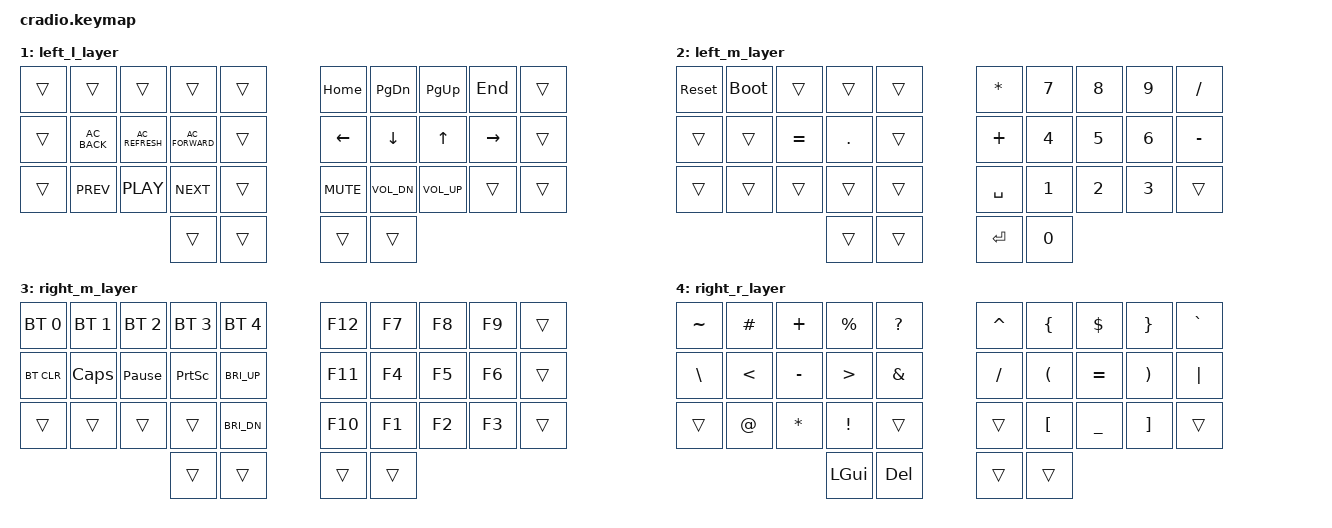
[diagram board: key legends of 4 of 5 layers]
// Copyright (c) 2022 The ZMK Contributors
// SPDX-License-Identifier: MIT

#include <behaviors.dtsi>
#include <dt-bindings/zmk/keys.h>
#include <dt-bindings/zmk/bt.h>

// Home row mods macro
#define HRML(k1,k2,k3,k4) &ht LGUI k1  &ht LALT k2  &ht LCTRL k3  &ht LSHFT k4
#define HRMR(k1,k2,k3,k4) &ht RSHFT k1  &ht RCTRL k2  &ht LALT k3  &ht RGUI k4

// Layers
#define DEFAULT 0
#define LEFT_L 1
#define LEFT_M 2
#define RIGHT_M 3
#define RIGHT_R 4

// Tapping term time
#define TAP_TERM 170

/ {
    behaviors {
        ht: hold_tap {
            compatible = "zmk,behavior-hold-tap";
            #binding-cells = <2>;
            flavor = "tap-preferred";
            tapping-term-ms = <TAP_TERM>;
            quick-tap-ms = <150>;
            require-prior-idle-ms = <100>;
            bindings = <&kp>, <&kp>;
        };
    };

    lt {
        tapping-term-ms = <TAP_TERM>;
    };

    // conditional_layers {
    //     compatible = "zmk,conditional-layers";
    //     tri_layer {
    //         if-layers = <1 2>;
    //         then-layer = <3>;
    //     };
    // };

    keymap {
        compatible = "zmk,keymap";
        default_layer {
            bindings = <
                //╭──────────┬──────────┬──────────┬──────────┬──────────╮   ╭──────────┬──────────┬──────────┬──────────┬──────────╮
                //│  W       │  L       │  Y       │  P       │  B       │   │  F       │  J       │  O       │  U       │  ' "     │
                &kp W      &kp L    &ht RALT Y   &kp P      &kp B          &kp F      &kp J     &ht RALT O    &kp U     &kp SQT
                //├──────────┼──────────┼──────────┼──────────┼──────────┤   ├──────────┼──────────┼──────────┼──────────┼──────────┤
                //│  C       │  R       │  S       │  T       │  G       │   │  M       │  N       │  E       │  I       │  A       │
                HRML(C,        R,         S,         T)     &kp G          &kp M      HRMR(N,        E,         I,        A)
                //├──────────┼──────────┼──────────┼──────────┼──────────┤   ├──────────┼──────────┼──────────┼──────────┼──────────┤
                //│  Q       │  Z       │  V       │  D       │  K       │   │  X       │  H       │ , <      │ . >      │ / ?      │
                &kp Q      &kp Z      &kp V      &kp D      &kp K          &kp X      &kp H      &kp SEMI   &kp COMMA   &kp DOT
                //╰──────────┴──────────┴──────────┼──────────┼──────────┤   ├──────────┼──────────┼──────────┴──────────┴──────────╯
                &lt LEFT_L TAB &lt LEFT_M SPACE &lt RIGHT_M BSPC &lt RIGHT_R ESC
                //                                 ╰──────────┴──────────╯   ╰──────────┴──────────╯
            >;
        };

        left_l_layer {
            bindings = <
                //╭──────────┬──────────┬──────────┬──────────┬──────────╮   ╭──────────┬──────────┬──────────┬──────────┬──────────╮
                //│          │          │          │          │          │   │  HOME    │PAGE DOWN │ PAGE UP  │  END     │          │
                &trans     &trans     &trans     &trans    &trans          &kp HOME   &kp PG_DN    &kp PG_UP   &kp END   &trans
                //├──────────┼──────────┼──────────┼──────────┼──────────┤   ├──────────┼──────────┼──────────┼──────────┼──────────┤
                //│          │  CAPS    │ PAUSE    │PRINT SCRN│          │   │  <-      │  v       │  ^       │  ->      │          │
                &trans &kp C_AC_BACK &kp C_AC_REFRESH &kp C_AC_FORWARD &trans  &kp LEFT  &kp DOWN  &kp UP     &kp RIGHT   &trans
                //├──────────┼──────────┼──────────┼──────────┼──────────┤   ├──────────┼──────────┼──────────┼──────────┼──────────┤
                //│          │MEDIA PREV│MEDIA PLAY│MEDIA NEXT│          │   │  MUTE    │VOL DOWN  │VOL UP    │          │          │
                &trans    &kp C_PREV &kp C_PLAY &kp C_NEXT   &trans       &kp C_MUTE &kp C_VOL_DN &kp C_VOL_UP &trans  &trans
                //╰──────────┴──────────┴──────────┼──────────┼──────────┤   ├──────────┼──────────┼──────────┴──────────┴──────────╯
                &trans     &trans         &trans     &trans
                //                                 ╰──────────┴──────────╯   ╰──────────┴──────────╯
            >;
        };

        left_m_layer {
            bindings = <
                //╭──────────┬──────────┬──────────┬──────────┬──────────╮   ╭──────────┬──────────┬──────────┬──────────┬──────────╮
                //│ RESET    │          │          │          │          │   │   *      │  7       │  8       │  9       │  /       │
                &sys_reset  &bootloader   &trans     &trans    &trans        &kp ASTRK   &kp N7     &kp N8      &kp N9    &kp FSLH
                //├──────────┼──────────┼──────────┼──────────┼──────────┤   ├──────────┼──────────┼──────────┼──────────┼──────────┤
                //│BOOTLOADER│          │  =       │  .       │          │   │   +      │  4       │  5       │  6       │  -       │
                &trans          &trans    &kp EQUAL  &kp DOT    &trans         &kp PLUS   &kp N4     &kp N5      &kp N6    &kp MINUS
                //├──────────┼──────────┼──────────┼──────────┼──────────┤   ├──────────┼──────────┼──────────┼──────────┼──────────┤
                //│          │          │          │          │          │   │ SPACE    │  1       │  2       │  3       │          │
                &trans     &trans     &trans     &trans     &trans        &kp SPACE    &kp N1    &kp N2      &kp N3      &trans
                //╰──────────┴──────────┴──────────┼──────────┼──────────┤   ├──────────┼──────────┼──────────┴──────────┴──────────╯
                &trans     &trans       &kp ENTER    &kp N0
                //                                 ╰──────────┴──────────╯   ╰──────────┴──────────╯
            >;
        };

        right_m_layer {
            bindings = <
                //╭──────────┬──────────┬──────────┬──────────┬──────────╮   ╭──────────┬──────────┬──────────┬──────────┬──────────╮
                //│PROFILE 0 │PROFILE 1 │PROFILE 2 │PROFILE 3 │PROFILE 4 │   │ F12      │ F7       │ F8       │ F9       │          │
                &bt BT_SEL 0 &bt BT_SEL 1 &bt BT_SEL 2 &bt BT_SEL 3 &bt BT_SEL 4  &kp F12    &kp F7     &kp F8     &kp F9     &trans
                //├──────────┼──────────┼──────────┼──────────┼──────────┤   ├──────────┼──────────┼──────────┼──────────┼──────────┤
                //│ DELETE   │  CAPS    │  BAUSE   │  PSCRN   │BRIGHT UP │   │ F11      │ F4       │ F5       │ F6       │          │
                &bt BT_CLR  &kp CAPS &kp PAUSE_BREAK  &kp PSCRN &kp C_BRI_UP     &kp F11    &kp F4     &kp F5     &kp F6     &trans
                //├──────────┼──────────┼──────────┼──────────┼──────────┤   ├──────────┼──────────┼──────────┼──────────┼──────────┤
                //│          │TO LAYER  │TO LAYER  │TO LAYER  │BRIGHT DWN│   │ F10      │ F1       │ F2       │ F3       │          │
                &trans     &trans     &trans     &trans   &kp C_BRI_DN     &kp F10     &kp F1     &kp F2     &kp F3    &trans
                //╰──────────┴──────────┴──────────┼──────────┼──────────┤   ├──────────┼──────────┼──────────┴──────────┴──────────╯
                &trans     &trans        &trans     &trans
                //                                 ╰──────────┴──────────╯   ╰──────────┴──────────╯
            >;
        };

        right_r_layer {
            bindings = <
                //╭──────────┬──────────┬──────────┬──────────┬──────────╮   ╭──────────┬──────────┬──────────┬──────────┬──────────╮
                //│  ~       │  #       │  +       │  %       │  ?       │   │  ^       │  {       │  $       │  }       │  `       │
                &kp TILDE  &kp HASH   &kp PLUS   &kp PRCNT   &kp QMARK        &kp CARET  &kp LBRC   &kp DLLR   &kp RBRC  &kp GRAVE
                //├──────────┼──────────┼──────────┼──────────┼──────────┤   ├──────────┼──────────┼──────────┼──────────┼──────────┤
                //│  \       │  <       │  -       │  >       │  &       │   │  /       │  (       │  =       │  )       │  |       │
                &kp BSLH   &kp LT    &kp MINUS   &kp GT     &kp AMPS       &kp FSLH  &kp LPAR   &kp EQUAL  &kp RPAR   &kp PIPE
                //├──────────┼──────────┼──────────┼──────────┼──────────┤   ├──────────┼──────────┼──────────┼──────────┼──────────┤
                //│          │  @       │  *       │  !       │          │   │          │  [       │  _       │  ]       │          │
                &trans     &kp AT     &kp ASTRK  &kp EXCL     &trans        &trans    &kp LBKT  &kp UNDER   &kp RBKT   &trans
                //╰──────────┴──────────┴──────────┼──────────┼──────────┤   ├──────────┼──────────┼──────────┴──────────┴──────────╯
                &kp LGUI    &kp DEL        &trans     &trans
                //                                 ╰──────────┴──────────╯   ╰──────────┴──────────╯
            >;
        };
    };
};
